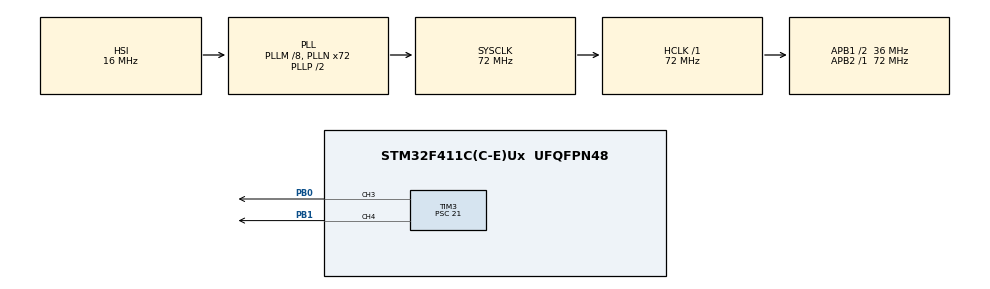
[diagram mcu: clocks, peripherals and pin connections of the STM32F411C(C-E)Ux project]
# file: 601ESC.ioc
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Mcu.Family=STM32F4
Mcu.Name=STM32F411C(C-E)Ux
Mcu.Package=UFQFPN48
NVIC.PriorityGroup=NVIC_PRIORITYGROUP_4
PA13.Mode=Serial_Wire
PA13.Signal=SYS_JTMS-SWDIO
PA14.Mode=Serial_Wire
PA14.Signal=SYS_JTCK-SWCLK
PB0.Signal=S_TIM3_CH3
PB1.Signal=S_TIM3_CH4
PH0\ -\ OSC_IN.Mode=HSE-External-Oscillator
PH0\ -\ OSC_IN.Signal=RCC_OSC_IN
PH1\ -\ OSC_OUT.Mode=HSE-External-Oscillator
PH1\ -\ OSC_OUT.Signal=RCC_OSC_OUT
ProjectManager.HeapSize=0x200
ProjectManager.StackSize=0x400
ProjectManager.TargetToolchain=STM32CubeIDE
RCC.48MHZClocksFreq_Value=36000000
RCC.AHBFreq_Value=72000000
RCC.APB1CLKDivider=RCC_HCLK_DIV2
RCC.APB1Freq_Value=36000000
RCC.APB1TimFreq_Value=72000000
RCC.APB2Freq_Value=72000000
RCC.APB2TimFreq_Value=72000000
RCC.CortexFreq_Value=72000000
RCC.HCLKFreq_Value=72000000
RCC.HSE_VALUE=25000000
RCC.HSI_VALUE=16000000
RCC.LSE_VALUE=32768
RCC.PLLM=8
RCC.PLLN=72
RCC.SYSCLKFreq_VALUE=72000000
RCC.SYSCLKSource=RCC_SYSCLKSOURCE_PLLCLK
RCC.VCOOutputFreq_Value=144000000
SH.S_TIM3_CH3.0=TIM3_CH3,PWM Generation3 CH3
SH.S_TIM3_CH4.0=TIM3_CH4,PWM Generation4 CH4
TIM3.AutoReloadPreload=TIM_AUTORELOAD_PRELOAD_ENABLE
TIM3.Channel-PWM\ Generation3\ CH3=TIM_CHANNEL_3
TIM3.Channel-PWM\ Generation4\ CH4=TIM_CHANNEL_4
TIM3.Period=65453
TIM3.Prescaler=21
VP_TIM3_VS_ClockSourceINT.Mode=Internal
board=custom

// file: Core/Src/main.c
/* USER CODE BEGIN Header */
/**
  ******************************************************************************
  * @file           : main.c
  * @brief          : Main program body
  ******************************************************************************
  * @attention
  *
  * Copyright (c) 2025 STMicroelectronics.
  * All rights reserved.
  *
  * This software is licensed under terms that can be found in the LICENSE file
  * in the root directory of this software component.
  * If no LICENSE file comes with this software, it is provided AS-IS.
  *
  ******************************************************************************
  */
/* USER CODE END Header */
#include "main.h"

TIM_HandleTypeDef htim3;

void SystemClock_Config(void);
static void MX_GPIO_Init(void);
static void MX_TIM3_Init(void);

/* USER CODE BEGIN 0 */

uint32_t motor_value = 0;
uint8_t motor_dir = 0;

#define ESC_MID 1800//2047 // Midpoint for ESC
#define ESC_FORWARD_MAX 3000//3000 // Minimum PWM value for ESC
#define ESC_INC 20 // Minimum PWM value for ESC

uint32_t map_esc_values(uint32_t au32_IN, uint32_t au32_INmin, uint32_t au32_INmax, uint32_t au32_OUTmin, uint32_t au32_OUTmax)
{
    return ((((au32_IN - au32_INmin)*(au32_OUTmax - au32_OUTmin))/(au32_INmax - au32_INmin)) + au32_OUTmin);
}

/* USER CODE END 0 */

int main(void)
{

  /* MCU Configuration--------------------------------------------------------*/

  /* Reset of all peripherals, Initializes the Flash interface and the Systick. */
  HAL_Init();

  /* Configure the system clock */
  SystemClock_Config();

  /* Initialize all configured peripherals */
  MX_GPIO_Init();
  MX_TIM3_Init();

  /* Infinite loop */
  /* USER CODE BEGIN WHILE */
  HAL_TIM_PWM_Start(&htim3, TIM_CHANNEL_3);

  motor_value = ESC_MID;

//  HAL_Delay(1000);
  TIM3->CCR3 = map_esc_values(motor_value, 0, 4095, 3273, 6545); // Map The ADC Reading To PWM DutyCycle
  // Inicia el PWM con el valor medio
  HAL_Delay(3000);
  while (1)
  {
    /* USER CODE END WHILE */

    /* USER CODE BEGIN 3 */
        if (motor_dir == 0) {
          motor_value += ESC_INC;
          if (motor_value >= ESC_FORWARD_MAX) {
             motor_dir = 1; // Cambia la dirección a reversa
          }
        }
        else {
          motor_value -= ESC_INC;
          if (motor_value <= ESC_MID) {
            motor_dir = 0; // Cambia la dirección a avance
          }
        }

        TIM3->CCR3 = map_esc_values(motor_value, 0, 4095, 3273, 6545); // Map The ADC Reading To PWM DutyCycle
        // Añade un pequeño retardo para no saturar el procesador
        HAL_Delay(2000); // Espera 100 milisegundos

  }
  /* USER CODE END 3 */
}

void SystemClock_Config(void)
{
  RCC_OscInitTypeDef RCC_OscInitStruct = {0};
  RCC_ClkInitTypeDef RCC_ClkInitStruct = {0};

  /** Configure the main internal regulator output voltage
  */
  __HAL_RCC_PWR_CLK_ENABLE();
  __HAL_PWR_VOLTAGESCALING_CONFIG(PWR_REGULATOR_VOLTAGE_SCALE1);

  /** Initializes the RCC Oscillators according to the specified parameters
  * in the RCC_OscInitTypeDef structure.
  */
  RCC_OscInitStruct.OscillatorType = RCC_OSCILLATORTYPE_HSI;
  RCC_OscInitStruct.HSIState = RCC_HSI_ON;
  RCC_OscInitStruct.HSICalibrationValue = RCC_HSICALIBRATION_DEFAULT;
  RCC_OscInitStruct.PLL.PLLState = RCC_PLL_ON;
  RCC_OscInitStruct.PLL.PLLSource = RCC_PLLSOURCE_HSI;
  RCC_OscInitStruct.PLL.PLLM = 8;
  RCC_OscInitStruct.PLL.PLLN = 72;
  RCC_OscInitStruct.PLL.PLLP = RCC_PLLP_DIV2;
  RCC_OscInitStruct.PLL.PLLQ = 4;
  if (HAL_RCC_OscConfig(&RCC_OscInitStruct) != HAL_OK)
  {
    Error_Handler();
  }

  /** Initializes the CPU, AHB and APB buses clocks
  */
  RCC_ClkInitStruct.ClockType = RCC_CLOCKTYPE_HCLK|RCC_CLOCKTYPE_SYSCLK
                              |RCC_CLOCKTYPE_PCLK1|RCC_CLOCKTYPE_PCLK2;
  RCC_ClkInitStruct.SYSCLKSource = RCC_SYSCLKSOURCE_PLLCLK;
  RCC_ClkInitStruct.AHBCLKDivider = RCC_SYSCLK_DIV1;
  RCC_ClkInitStruct.APB1CLKDivider = RCC_HCLK_DIV2;
  RCC_ClkInitStruct.APB2CLKDivider = RCC_HCLK_DIV1;

  if (HAL_RCC_ClockConfig(&RCC_ClkInitStruct, FLASH_LATENCY_2) != HAL_OK)
  {
    Error_Handler();
  }
}

static void MX_TIM3_Init(void)
{

  TIM_ClockConfigTypeDef sClockSourceConfig = {0};
  TIM_MasterConfigTypeDef sMasterConfig = {0};
  TIM_OC_InitTypeDef sConfigOC = {0};

  htim3.Instance = TIM3;
  htim3.Init.Prescaler = 21;
  htim3.Init.CounterMode = TIM_COUNTERMODE_UP;
  htim3.Init.Period = 65453;
  htim3.Init.ClockDivision = TIM_CLOCKDIVISION_DIV1;
  htim3.Init.AutoReloadPreload = TIM_AUTORELOAD_PRELOAD_ENABLE;
  if (HAL_TIM_Base_Init(&htim3) != HAL_OK)
  {
    Error_Handler();
  }
  sClockSourceConfig.ClockSource = TIM_CLOCKSOURCE_INTERNAL;
  if (HAL_TIM_ConfigClockSource(&htim3, &sClockSourceConfig) != HAL_OK)
  {
    Error_Handler();
  }
  if (HAL_TIM_PWM_Init(&htim3) != HAL_OK)
  {
    Error_Handler();
  }
  sMasterConfig.MasterOutputTrigger = TIM_TRGO_RESET;
  sMasterConfig.MasterSlaveMode = TIM_MASTERSLAVEMODE_DISABLE;
  if (HAL_TIMEx_MasterConfigSynchronization(&htim3, &sMasterConfig) != HAL_OK)
  {
    Error_Handler();
  }
  sConfigOC.OCMode = TIM_OCMODE_PWM1;
  sConfigOC.Pulse = 0;
  sConfigOC.OCPolarity = TIM_OCPOLARITY_HIGH;
  sConfigOC.OCFastMode = TIM_OCFAST_DISABLE;
  if (HAL_TIM_PWM_ConfigChannel(&htim3, &sConfigOC, TIM_CHANNEL_3) != HAL_OK)
  {
    Error_Handler();
  }
  if (HAL_TIM_PWM_ConfigChannel(&htim3, &sConfigOC, TIM_CHANNEL_4) != HAL_OK)
  {
    Error_Handler();
  }
  HAL_TIM_MspPostInit(&htim3);

}

static void MX_GPIO_Init(void)
{

  /* GPIO Ports Clock Enable */
  __HAL_RCC_GPIOH_CLK_ENABLE();
  __HAL_RCC_GPIOB_CLK_ENABLE();
  __HAL_RCC_GPIOA_CLK_ENABLE();

}

void Error_Handler(void)
{
  __disable_irq();
  while (1)
  {
  }
}
